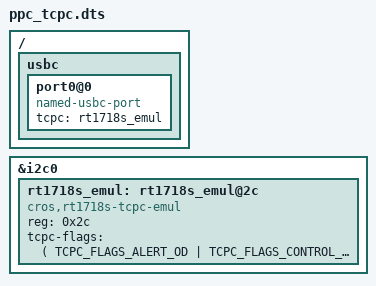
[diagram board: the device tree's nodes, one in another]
/* Copyright 2022 The ChromiumOS Authors
 * Use of this source code is governed by a BSD-style license that can be
 * found in the LICENSE file.
 */

#include <dt-bindings/usb_pd_tcpm.h>

/ {
	usbc {
		port0@0 {
			compatible = "named-usbc-port";
			tcpc = <&rt1718s_emul>;
		};
	};
};

&i2c0 {
	status="okay";

	rt1718s_emul: rt1718s_emul@2c {
		compatible = "cros,rt1718s-tcpc-emul", "richtek,rt1718s-tcpc";

		status = "okay";

		reg = <0x2c>;
		tcpc-flags = <(
			TCPC_FLAGS_ALERT_OD |
			TCPC_FLAGS_CONTROL_VCONN |
			TCPC_FLAGS_CONTROL_FRS)>;
	};
};
